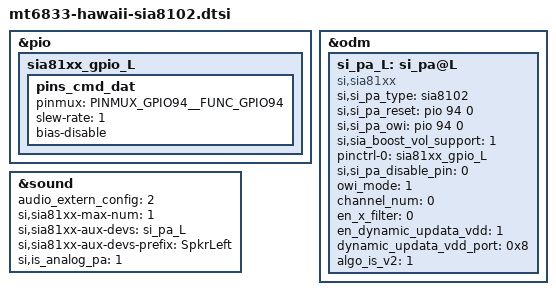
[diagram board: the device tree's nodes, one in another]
/* Copyright (c) 2018, The Linux Foundation. All rights reserved.
 *
 * This program is free software; you can redistribute it and/or modify
 * it under the terms of the GNU General Public License version 2 and
 * only version 2 as published by the Free Software Foundation.
 *
 * This program is distributed in the hope that it will be useful,
 * but WITHOUT ANY WARRANTY; without even the implied warranty of
 * MERCHANTABILITY or FITNESS FOR A PARTICULAR PURPOSE.  See the
 * GNU General Public License for more details.
 */

&pio {
	sia81xx_gpio_L: sia81xx_gpio_L {
		pins_cmd_dat {
			pinmux = <PINMUX_GPIO94__FUNC_GPIO94>;
			slew-rate = <1>;
			bias-disable;
		};
	};
};

&odm {
	si_pa_L: si_pa@L {
		compatible = "si,sia81xx";
		si,si_pa_type = "sia8102";
		si,si_pa_reset = <&pio 94 0>;
		si,si_pa_owi = <&pio 94 0>;
		si,sia_boost_vol_support = <1>;
		pinctrl-names = "si_pa_gpio";
		pinctrl-0 = <&sia81xx_gpio_L>;
		si,si_pa_disable_pin = <0>;
		owi_mode = <1>;
		channel_num = <0>;
		en_x_filter = <0>;
		en_dynamic_updata_vdd = <1>;
		dynamic_updata_vdd_port = <0x8>;
		algo_is_v2 = <1>;
	};
};

&sound {
	audio_extern_config = <2>;
	si,sia81xx-max-num = <1>;
	si,sia81xx-aux-devs = <&si_pa_L>;
	si,sia81xx-aux-devs-prefix = "SpkrLeft";
	si,is_analog_pa = <1>;
};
